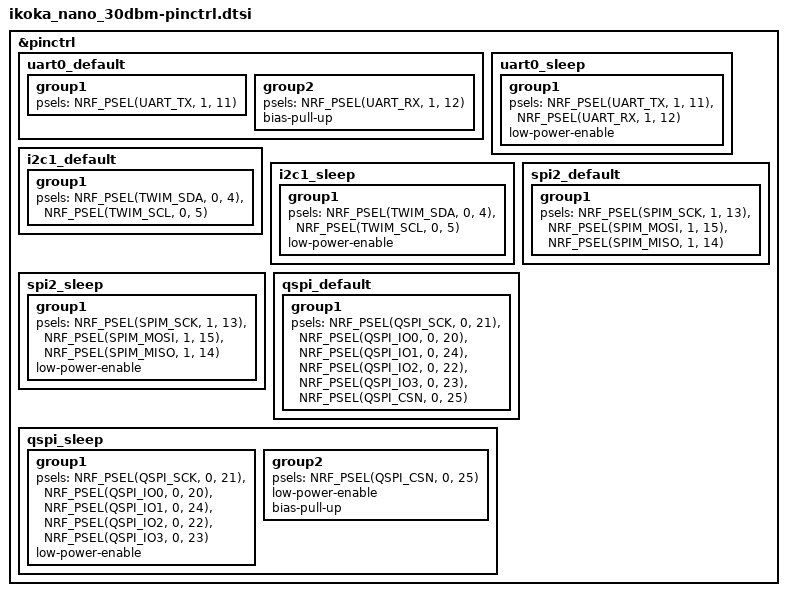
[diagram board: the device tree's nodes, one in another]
/*
 * SPDX-License-Identifier: MIT
 * Ikoka Nano 30dBm pin control - based on XIAO nRF52840
 */

&pinctrl {
	/* UART0 on D6/D7 (optional, shared with LoRa RXEN) */
	uart0_default: uart0_default {
		group1 {
			psels = <NRF_PSEL(UART_TX, 1, 11)>;  /* D6 = P1.11 */
		};
		group2 {
			psels = <NRF_PSEL(UART_RX, 1, 12)>;  /* D7 = P1.12 */
			bias-pull-up;
		};
	};

	uart0_sleep: uart0_sleep {
		group1 {
			psels = <NRF_PSEL(UART_TX, 1, 11)>,
				<NRF_PSEL(UART_RX, 1, 12)>;
			low-power-enable;
		};
	};

	/* I2C1 on D4/D5 for external sensors */
	i2c1_default: i2c1_default {
		group1 {
			psels = <NRF_PSEL(TWIM_SDA, 0, 4)>,   /* D4 = P0.04 */
				<NRF_PSEL(TWIM_SCL, 0, 5)>;  /* D5 = P0.05 */
		};
	};

	i2c1_sleep: i2c1_sleep {
		group1 {
			psels = <NRF_PSEL(TWIM_SDA, 0, 4)>,
				<NRF_PSEL(TWIM_SCL, 0, 5)>;
			low-power-enable;
		};
	};

	/* SPI2 for LoRa on D8/D9/D10 */
	spi2_default: spi2_default {
		group1 {
			psels = <NRF_PSEL(SPIM_SCK, 1, 13)>,   /* D8 = P1.13 */
				<NRF_PSEL(SPIM_MOSI, 1, 15)>,  /* D10 = P1.15 */
				<NRF_PSEL(SPIM_MISO, 1, 14)>;  /* D9 = P1.14 */
		};
	};

	spi2_sleep: spi2_sleep {
		group1 {
			psels = <NRF_PSEL(SPIM_SCK, 1, 13)>,
				<NRF_PSEL(SPIM_MOSI, 1, 15)>,
				<NRF_PSEL(SPIM_MISO, 1, 14)>;
			low-power-enable;
		};
	};

	/* QSPI for onboard flash */
	qspi_default: qspi_default {
		group1 {
			psels = <NRF_PSEL(QSPI_SCK, 0, 21)>,
				<NRF_PSEL(QSPI_IO0, 0, 20)>,
				<NRF_PSEL(QSPI_IO1, 0, 24)>,
				<NRF_PSEL(QSPI_IO2, 0, 22)>,
				<NRF_PSEL(QSPI_IO3, 0, 23)>,
				<NRF_PSEL(QSPI_CSN, 0, 25)>;
		};
	};

	qspi_sleep: qspi_sleep {
		group1 {
			psels = <NRF_PSEL(QSPI_SCK, 0, 21)>,
				<NRF_PSEL(QSPI_IO0, 0, 20)>,
				<NRF_PSEL(QSPI_IO1, 0, 24)>,
				<NRF_PSEL(QSPI_IO2, 0, 22)>,
				<NRF_PSEL(QSPI_IO3, 0, 23)>;
			low-power-enable;
		};
		group2 {
			psels = <NRF_PSEL(QSPI_CSN, 0, 25)>;
			low-power-enable;
			bias-pull-up;
		};
	};
};
